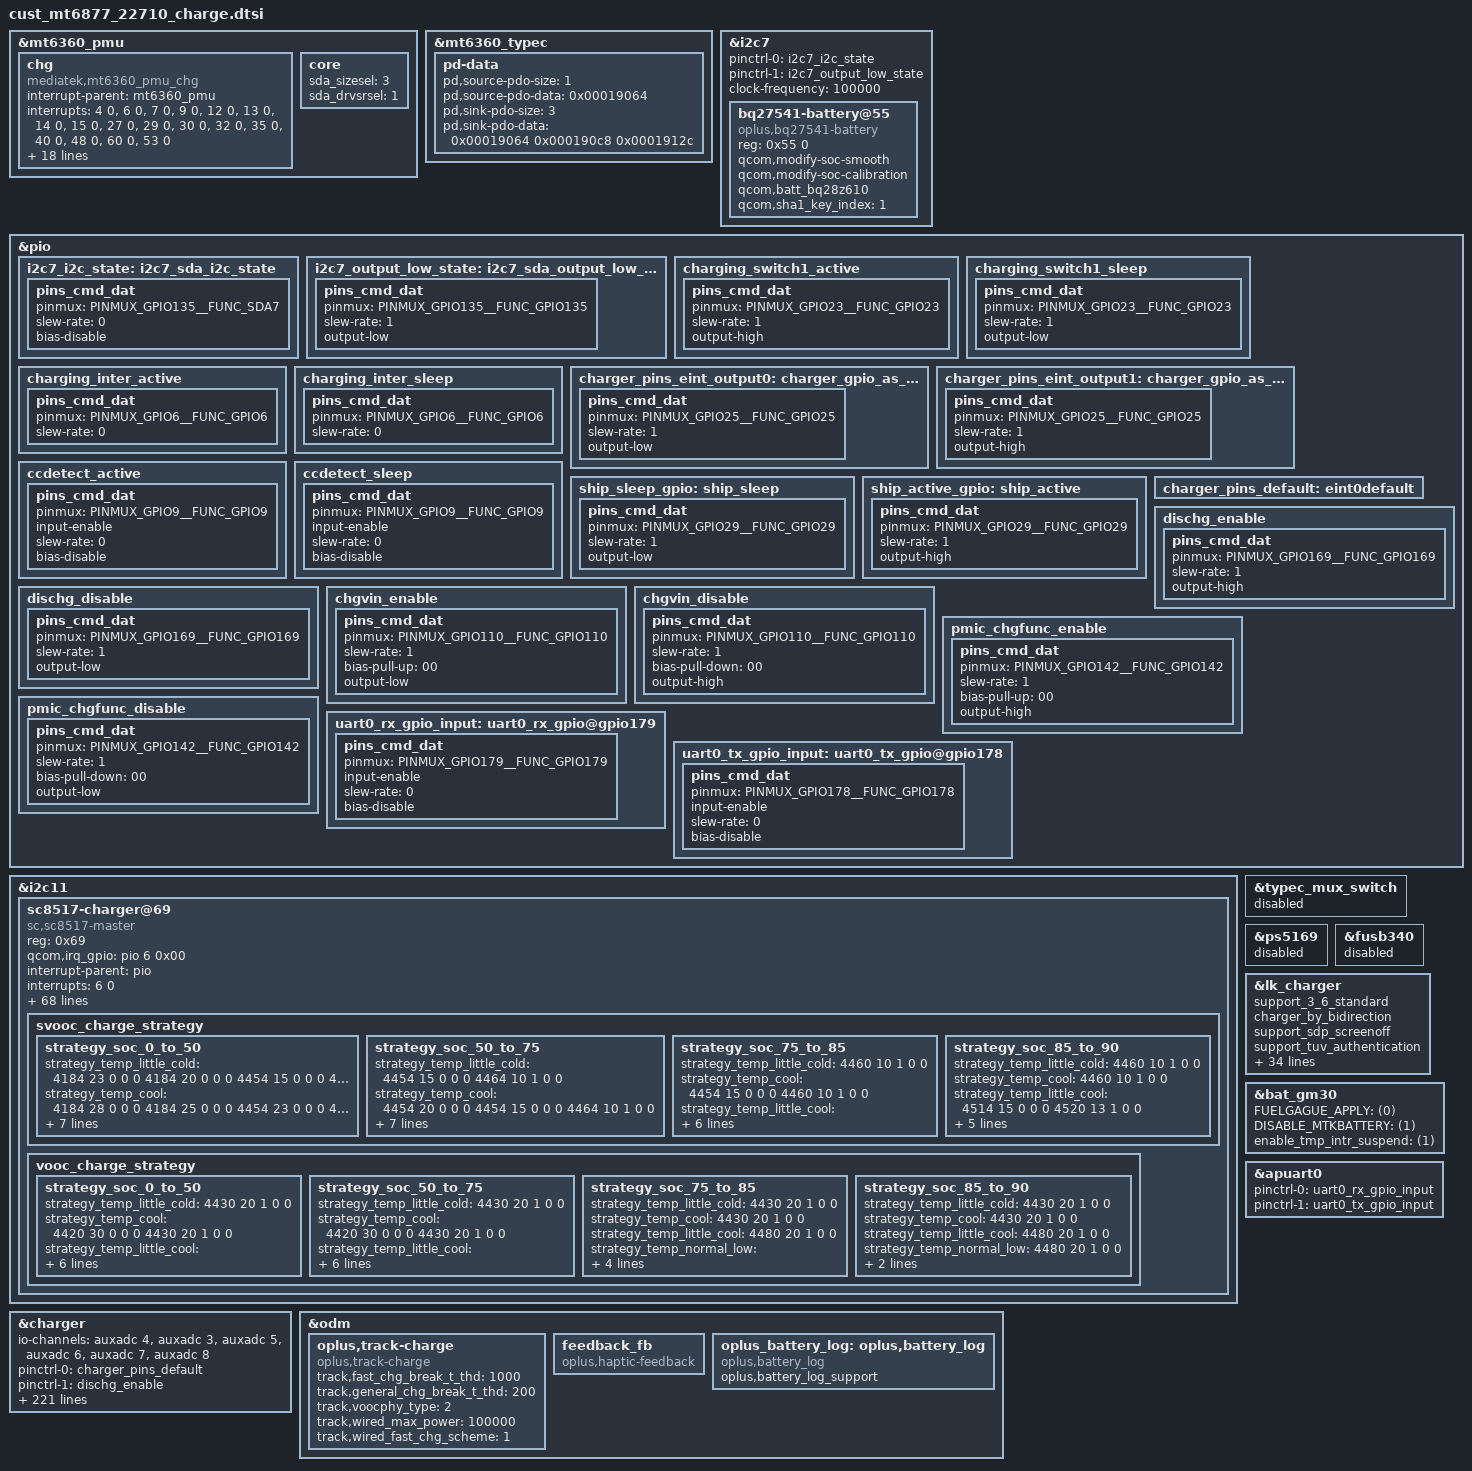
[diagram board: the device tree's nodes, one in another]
&mt6360_pmu {
	chg {
		compatible = "mediatek,mt6360_pmu_chg";
		interrupt-parent = <&mt6360_pmu>;
		interrupts = <4 0>, <6 0>, <7 0>, <9 0>,
				<12 0>, <13 0>, <14 0>, <15 0>,
				<27 0>, <29 0>, <30 0>, <32 0>,
				<35 0>, <40 0>, <48 0>, <60 0>,
				<53 0>;
		interrupt-names = "chg_treg_evt", "chg_mivr_evt",
				"pwr_rdy_evt", "chg_batsysuv_evt",
				"chg_vsysuv_evt", "chg_vsysov_evt",
				"chg_vbatov_evt", "chg_vbusov_evt",
				"chg_tmri", "chg_adpbadi",
				"chg_rvpi",  "chg_aiccmeasl",
				"wdtmri", "pumpx_donei",
				"attachi", "chrdet_ext_evt",
				"hvdcp_det";
		io-channels = <&adc 0>, <&adc 1>, <&adc 3>, <&adc 4>,
				<&adc 5>, <&adc 6>, <&adc 8>, <&adc 10>;
		io-channel-names = "USBID", "VBUSDIV5", "VSYS", "VBAT",
				"IBUS", "IBAT", "TEMP_JC", "TS";
		chg_name = "primary_chg";
		ichg = <2000000>;               /* uA */
		aicr = <500000>;                /* uA */
		mivr = <4400000>;               /* uV */
		cv = <4350000>;                 /* uA */
		ieoc = <150000>;                /* uA */
		safety_timer = <12>;            /* hour */
		ircmp_resistor = <25000>;       /* uohm */
		ircmp_vclamp = <32000>;         /* uV */
		en_te = <1>;
		en_wdt = <1>;
		aicc_once = <1>;
		post_aicc = <1>;
		batoc_notify = <0>;
	};
};

&mt6360_typec {
	pd-data {
		pd,source-pdo-size = <1>;
		pd,source-pdo-data = <0x00019064>; /* Fixed5V1A */

		pd,sink-pdo-size = <3>;
		pd,sink-pdo-data = <0x00019064 0x000190c8 0x0001912c>; /* Fixed5V1A Fixed5V2A Fixed5V3A */
	};
};

&mt6360_pmu {
	core {
		sda_sizesel = <3>;
		sda_drvsrsel = <1>;
	};
	chg {
		support_hvdcp;
		cdp_first_ignore;
	};
};

&i2c7 {
	pinctrl-names = "i2c-state", "output-low-state";
	pinctrl-0 = <&i2c7_i2c_state>;
	pinctrl-1 = <&i2c7_output_low_state>;
};
&pio {
	i2c7_i2c_state: i2c7_sda_i2c_state {
		pins_cmd_dat {
			pinmux = <PINMUX_GPIO135__FUNC_SDA7>;
			slew-rate = <0>;
			bias-disable;
		};
	};
	i2c7_output_low_state: i2c7_sda_output_low_state {
		pins_cmd_dat {
			pinmux = <PINMUX_GPIO135__FUNC_GPIO135>;
			slew-rate = <1>;
			output-low;
		};
	};
};

&i2c7 {
	status = "okay";
	clock-frequency = <100000>;

	bq27541-battery@55 {
		status = "okay";
		compatible = "oplus,bq27541-battery";
		reg = <0x55 0>;
		qcom,modify-soc-smooth;
		qcom,modify-soc-calibration;
		qcom,batt_bq28z610;
		qcom,sha1_key_index = <1>;
		//qcom,bq28z610_need_balancing;
	};
};

&i2c11 {
	sc8517-charger@69{
		status = "okay";
		compatible = "sc,sc8517-master";
		reg = <0x69>;

		qcom,irq_gpio = <&pio 6 0x00>;
		interrupt-parent = <&pio>;
		interrupts = <6 0>;

		pinctrl-names = "switch1_act_switch2_act", "switch1_sleep_switch2_sleep",
				"charging_inter_active", "charging_inter_sleep";
		pinctrl-0 = <&charging_switch1_active>;
		pinctrl-1 = <&charging_switch1_sleep>;
		pinctrl-2 = <&charging_inter_active>;
		pinctrl-3 = <&charging_inter_sleep>;

		qcom,charging_switch1-gpio = <&pio 23 0x00>;

		qcom,external_gauge_support;
		qcom,copycat_vooc_support;
		qcom,voocphy_bidirect_cp_support;
		qcom,voocphy_current_default = <100>;

		qcom,svooc_cool_down_current_limit = <100 10 15 20 25 30 35 40 45 50 55 60 63 65 70 75 80 85 100>;
		qcom,vooc_cool_down_current_limit = <60 20 20 20 30 40 50 60>;

		qcom,abnormal_adapter_current = <122 50 50 50 40 40 30 30 20 20>;
		qcom,vooc_little_cold_full_voltage = <4460>;
		qcom,vooc_cool_full_voltage = <4460>;
		qcom,vooc_warm_full_voltage = <4130>;
		qcom,vooc_1time_full_voltage = <4530>;
		qcom,vooc_ntime_full_voltage = <4520>;
		qcom,low_curr_full_t1 = <120>;
		qcom,low_curr_full_t2 = <350>;
		qcom,low_curr_full_t3 = <430>;
		qcom,range1_low_curr_full = <1000 4490
						950 4485
						800 4470
						700 4460
						500 4450>;
		qcom,range2_low_curr_full = <1150 4490
						1100 4485
						950 4470
						850 4460
						650 4450>;

		qcom,vooc_multistep_initial_batt_temp = <1000>;
		qcom,vooc_little_cool_temp = <200>;
		qcom,vooc_cool_temp = <120>;
		qcom,vooc_little_cold_temp = <50>;
		qcom,vooc_normal_low_temp = <350>;
		qcom,vooc_strategy_normal_current = <100>;
		qcom,vooc_normal_to_little_cool_current = <100>;
		qcom,vooc_batt_over_high_temp = <510>;
		qcom,vooc-low-temp = <0>;
		qcom,vooc-high-temp = <500>;
		qcom,vooc-low-soc = <0>;
		qcom,vooc-high-soc = <90>;
		qcom,vooc-normal-high-temp = <430>;
		qcom,vooc-warm-allow-vol = <4000>;
		qcom,vooc-warm-allow-soc = <50>;

		qcom,vooc_strategy1_batt_high_temp0 = <380>;
		qcom,vooc_strategy1_batt_high_temp1 = <400>;
		qcom,vooc_strategy1_batt_high_temp2 = <420>;
		qcom,vooc_strategy1_batt_low_temp2 = <410>;
		qcom,vooc_strategy1_batt_low_temp1 = <390>;
		qcom,vooc_strategy1_batt_low_temp0 = <370>;

		qcom,vooc_strategy1_high_current0 = <70>;
		qcom,vooc_strategy1_high_current1 = <60>;
		qcom,vooc_strategy1_high_current2 = <50>;
		qcom,vooc_strategy1_low_current2 = <60>;
		qcom,vooc_strategy1_low_current1 = <70>;
		qcom,vooc_strategy1_low_current0 = <80>;

		qcom,voocphy_ibat_over_current = <10600>;
		qcom,voocphy_cp_max_ibus = <6300>;
		qcom,voocphy_svooc_cp_max_ibus = <3500>;
		qcom,voocphy_vooc_cp_max_ibus = <3500>;
		qcom,batt_pwd_curr_thd1 = <3300>;
		qcom,batt_pwd_vol_thd1 = <4514>;

		qcom,voocphy_freq_mincore = <1800000>;
		qcom,voocphy_freq_midcore = <1800000>;
		qcom,voocphy_freq_maxcore = <1800000>;
		qcom,voocphy_current_change_timeout = <100>;

		svooc_batt_sys_curve = <1 0 1 0 0 0 0	// 8000mA
					1 0 1 1 1 0 0	// 4324mV
					0 0 1 0 1 0 0	// 2000mA
					1 1 1 0 0 1 0	// 4544mV
					0 0 0 1 1 0 0	// 1200mA
					1 1 1 0 0 1 0>; // 4544mV

		vooc_batt_sys_curve =  <0 1 0 1 1 0 1 	// 3000mA
					0 0 0 0 0 0 1	// 3414mV
					0 0 1 0 1 0 0	// 2000mA
					1 1 1 0 0 1 0	// 4544mV
					0 0 0 1 0 1 0	// 1000mA
					1 1 1 0 0 1 0>; // 4544mV

		svooc_charge_strategy {
			strategy_soc_0_to_50 {
				strategy_temp_little_cold =	<4184 23 0 0 0
								4184 20 0 0 0
								4454 15 0 0 0
								4460 10 1 0 0>;
				strategy_temp_cool =		<4184 28 0 0 0
								4184 25 0 0 0
								4454 23 0 0 0
								4454 20 0 0 0
								4454 15 0 0 0
								4460 10 1 0 0>;
				strategy_temp_little_cool = 	<4184 65 0 0 0
								4184 60 0 0 0
								4184 55 0 0 0
								4184 50 0 0 0
								4484 45 0 0 0
								4484 40 0 0 0
								4484 35 0 0 0
								4514 30 0 0 0
								4514 25 0 0 0
								4514 20 0 0 0
								4514 15 0 0 0
								4520 13 1 0 0>;
				strategy_temp_normal_low =	<4204 91 0 180 0
								4204 85 0 180 0
								4304 80 0 180 0
								4304 75 0 180 0
								4304 70 0 600 0
								4304 65 0 600 0
								4484 60 0 0 0
								4484 55 0 0 0
								4484 50 0 0 0
								4484 45 0 0 0
								4514 40 0 0 0
								4514 35 0 0 0
								4514 30 0 0 0
								4514 25 0 0 0
								4514 20 0 0 0
								4514 15 0 0 0
								4520 13 1 0 0>;
				strategy_temp_normal_high =	<4204 91 0 180 0
								4204 85 0 180 0
								4304 80 0 180 0
								4304 75 0 180 0
								4304 70 0 600 0
								4304 65 0 600 0
								4484 60 0 0 0
								4484 55 0 0 0
								4484 50 0 0 0
								4484 45 0 0 0
								4514 40 0 0 0
								4514 35 0 0 0
								4514 30 0 0 0
								4514 25 0 0 0
								4514 20 0 0 0
								4520 15 1 0 0>;
				strategy_temp_warm =		<4130 13 1 0 0>;
			};

			strategy_soc_50_to_75 {
				strategy_temp_little_cold =	<4454 15 0 0 0
								4464 10 1 0 0>;
				strategy_temp_cool =		<4454 20 0 0 0
								4454 15 0 0 0
								4464 10 1 0 0>;
				strategy_temp_little_cool =	<4484 45 0 0 0
								4484 40 0 0 0
								4484 35 0 0 0
								4514 30 0 0 0
								4514 25 0 0 0
								4514 20 0 0 0
								4514 15 0 0 0
								4520 13 1 0 0>;
				strategy_temp_normal_low =	<4484 50 0 0 0
								4484 45 0 0 0
								4514 40 0 0 0
								4514 35 0 0 0
								4514 30 0 0 0
								4514 25 0 0 0
								4514 20 0 0 0
								4514 15 0 0 0
								4520 13 1 0 0>;
				strategy_temp_normal_high =	<4484 50 0 0 0
								4484 45 0 0 0
								4514 40 0 0 0
								4514 35 0 0 0
								4514 30 0 0 0
								4514 25 0 0 0
								4514 20 0 0 0
								4520 15 1 0 0>;
				strategy_temp_warm =		<4130 12 1 0 0>;
			};

			strategy_soc_75_to_85 {
				strategy_temp_little_cold = 	<4460 10 1 0 0>;
				strategy_temp_cool =		<4454 15 0 0 0
								4460 10 1 0 0>;
				strategy_temp_little_cool =	<4514 30 0 0 0
								4514 25 0 0 0
								4514 20 0 0 0
								4514 15 0 0 0
								4520 13 1 0 0>;
				strategy_temp_normal_low =	<4514 35 0 0 0
								4514 30 0 0 0
								4514 25 0 0 0
								4514 20 0 0 0
								4514 15 0 0 0
								4520 13 1 0 0>;
				strategy_temp_normal_high =	<4514 35 0 0 0
								4514 30 0 0 0
								4514 25 0 0 0
								4514 20 0 0 0
								4520 15 1 0 0>;
				strategy_temp_warm =		<4130 12 1 0 0>;
			};

			strategy_soc_85_to_90 {
				strategy_temp_little_cold = 	<4460 10 1 0 0>;
				strategy_temp_cool =		<4460 10 1 0 0>;
				strategy_temp_little_cool =	<4514 15 0 0 0
					            4520 13 1 0 0>;
				strategy_temp_normal_low =	<4514 20 0 0 0
					            4514 15 0 0 0
								4520 13 1 0 0>;
				strategy_temp_normal_high =	<4514 20 0 0 0
								4520 15 1 0 0>;
				strategy_temp_warm =		<4130 12 1 0 0>;
			};
		};

		vooc_charge_strategy {
			strategy_soc_0_to_50 {
				strategy_temp_little_cold = 	<4430 20 1 0 0>;
				strategy_temp_cool =		<4420 30 0 0 0
								 4430 20 1 0 0>;
				strategy_temp_little_cool =	<4475 30 0 0 0
								 4480 20 1 0 0>;
				strategy_temp_normal_low =	<4475 30 0 0 0
								 4480 20 1 0 0>;
				strategy_temp_normal_high =	<4475 30 0 0 0
								 4480 20 1 0 0>;
				strategy_temp_warm =		<4130 24 1 0 0>;
			};

			strategy_soc_50_to_75 {
				strategy_temp_little_cold =	<4430 20 1 0 0>;
				strategy_temp_cool =		<4420 30 0 0 0
								 4430 20 1 0 0>;
				strategy_temp_little_cool =	<4475 30 0 0 0
								 4480 20 1 0 0>;
				strategy_temp_normal_low =	<4475 30 0 0 0
								 4480 20 1 0 0>;
				strategy_temp_normal_high =	<4475 30 0 0 0
								 4480 20 1 0 0>;
				strategy_temp_warm =		<4130 24 1 0 0>;
			};

			strategy_soc_75_to_85 {
				strategy_temp_little_cold =	<4430 20 1 0 0>;
				strategy_temp_cool =		<4430 20 1 0 0>;
				strategy_temp_little_cool =	<4480 20 1 0 0>;
				strategy_temp_normal_low =	<4475 30 0 0 0
								 4480 20 1 0 0>;
				strategy_temp_normal_high =	<4475 30 0 0 0
								 4480 20 1 0 0>;
				strategy_temp_warm =		<4130 24 1 0 0>;
			};

			strategy_soc_85_to_90 {
				strategy_temp_little_cold =	<4430 20 1 0 0>;
				strategy_temp_cool =		<4430 20 1 0 0>;
				strategy_temp_little_cool =	<4480 20 1 0 0>;
				strategy_temp_normal_low =	<4480 20 1 0 0>;
				strategy_temp_normal_high =	<4480 20 1 0 0>;
				strategy_temp_warm =		<4130 24 1 0 0>;
			};
		};
	};
};

&typec_mux_switch {
	status = "disabled";
};

&ps5169{
	status = "disabled";
};

&fusb340 {
	status = "disabled";
};

&pio {
	charging_switch1_active: charging_switch1_active {
		pins_cmd_dat {
			pinmux = <PINMUX_GPIO23__FUNC_GPIO23>;
			slew-rate = <1>;
			output-high;
		};
	};
	charging_switch1_sleep: charging_switch1_sleep {
		pins_cmd_dat {
			pinmux = <PINMUX_GPIO23__FUNC_GPIO23>;
			slew-rate = <1>;
			output-low;
		};
	};

	charging_inter_active: charging_inter_active {
		pins_cmd_dat {
			pinmux = <PINMUX_GPIO6__FUNC_GPIO6>;
			slew-rate = <0>;
        };
    };
	charging_inter_sleep: charging_inter_sleep {
		pins_cmd_dat {
            pinmux = <PINMUX_GPIO6__FUNC_GPIO6>;
            slew-rate = <0>;
        };
    };

	charger_pins_eint_output0: charger_gpio_as_output_low {
		pins_cmd_dat {
			pinmux = <PINMUX_GPIO25__FUNC_GPIO25>;
			slew-rate = <1>;
			output-low;
		};
	};

	charger_pins_eint_output1: charger_gpio_as_output_high {
		pins_cmd_dat {
			pinmux = <PINMUX_GPIO25__FUNC_GPIO25>;
			slew-rate = <1>;
			output-high;
		};
	};
	ccdetect_active: ccdetect_active {
		pins_cmd_dat {
			pinmux = <PINMUX_GPIO9__FUNC_GPIO9>;
			input-enable;
			slew-rate = <0>;
			bias-disable;
		};
	};
	ccdetect_sleep: ccdetect_sleep {
		pins_cmd_dat {
			pinmux = <PINMUX_GPIO9__FUNC_GPIO9>;
			input-enable;
			slew-rate = <0>;
			bias-disable;
		};
	};

	ship_sleep_gpio: ship_sleep {
		pins_cmd_dat {
			pinmux = <PINMUX_GPIO29__FUNC_GPIO29>;
			slew-rate = <1>;
			output-low;
		};
	};

	ship_active_gpio: ship_active {
		pins_cmd_dat {
			pinmux = <PINMUX_GPIO29__FUNC_GPIO29>;
			slew-rate = <1>;
			output-high;
		};
	};
};

&charger {
	io-channels =  <&auxadc 4>,<&auxadc 3>, <&auxadc 5>,
		<&auxadc 6>, <&auxadc 7>, <&auxadc 8>;
	io-channel-names = "auxadc6-subboard_temp","auxadc3-chargeric_temp","auxadc4-usb_temp_v_l",
		"auxadc5-usb_temp_v_r","usbcon_temp","batcon_temp";

	pinctrl-names = "default",
				"dischg_enable",
				"dischg_disable",
				"charger_gpio_as_output_low",
				"charger_gpio_as_output_high",
				"ccdetect_active",
				"ccdetect_sleep",
				"chgvin_enable",
				"chgvin_disable",
				"pmic_chgfunc_enable",
				"pmic_chgfunc_disable",
				"ship_active",
				"ship_sleep";
	pinctrl-0 = <&charger_pins_default>;
	pinctrl-1 = <&dischg_enable>;
	pinctrl-2 = <&dischg_disable>;
	pinctrl-3 = <&charger_pins_eint_output0>;
	pinctrl-4 = <&charger_pins_eint_output1>;
	pinctrl-5 = <&ccdetect_active>;
	pinctrl-6 = <&ccdetect_sleep>;
	pinctrl-7 = <&chgvin_enable>;
	pinctrl-8 = <&chgvin_disable>;
	pinctrl-9 = <&pmic_chgfunc_enable>;
	pinctrl-10 = <&pmic_chgfunc_disable>;
	pinctrl-11 = <&ship_active_gpio>;
	pinctrl-12 = <&ship_sleep_gpio>;

	qcom,pd_input_current_charger_ma = <1500>;
	qcom,qc_input_current_charger_ma = <1500>;
	qcom,input_current_charger_ma = <2000>;
	qcom,input_current_usb_ma = <500>;
	qcom,input_current_cdp_ma = <1500>;
	qcom,input_current_camera_ma = <1200>;
	qcom,input_current_calling_ma = <1500>;

	qcom,led_warm_bat_decidegc = <350>;
	qcom,led_high_bat_decidegc = <370>;
	qcom,input_current_led_ma = <1200>;
	qcom,input_current_led_ma_high = <1200>;
	qcom,input_current_led_ma_warm = <1500>;
	qcom,input_current_led_ma_normal = <2300>;
	qcom,input_current_led_ma_forcmcc = <500>;
	qcom,input_current_led_ma_limit_high = <1200>;

	qcom,vooc_temp_bat_normal_decidegc = <350>;
	qcom,vooc_temp_bat_warm_decidegc = <370>;
	qcom,vooc_temp_bat_hot_decidegc = <510>;
	qcom,input_current_vooc_led_ma_high = <1200>;
	qcom,input_current_vooc_led_ma_warm = <1800>;
	qcom,input_current_vooc_led_ma_normal = <3600>;
	qcom,input_current_vooc_ma_normal = <3600>;
	qcom,input_current_vooc_ma_warm = <3200>;
	qcom,input_current_vooc_ma_high = <2200>;

	qcom,overtemp_bat_decidegc = <350>;
	qcom,iterm_disabled = <0>;
	//sw_full_count = <25>;
	qcom,iterm_ma = <132>;
	qcom,recharge-mv = <100>;

	qcom,batt_capacity_mah = <5000>; /*typical capacity*/
	//qcom,batt_capacity_mah = <4880>; /*rated capacity*/
	qcom,usb_high_than_bat_decidegc = <168>;

	qcom,removed_bat_decidegc = <390>;  /* < -15C */

	qcom,cold_bat_decidegc = <100>;  /* -2C ~ 0C */
	qcom,temp_cold_vfloat_mv = <4465>;
	qcom,temp_cold_fastchg_current_ma = <1000>;

	qcom,little_cold_bat_decidegc = <0>;    /* 0C ~ 5C */
	qcom,temp_little_cold_vfloat_mv = <4465>;
	qcom,temp_little_cold_fastchg_current_ma_high = <2200>;
	qcom,temp_little_cold_fastchg_current_ma_low = <2200>;
	qcom,temp_little_cold_fastchg_current_ma = <1076>;
	qcom,qc_temp_little_cold_fastchg_current_ma_high = <2594>;
	qcom,qc_temp_little_cold_fastchg_current_ma_low = <3300>;
	qcom,pd_temp_little_cold_fastchg_current_ma_high = <2594>;
	qcom,pd_temp_little_cold_fastchg_current_ma_low = <3300>;

	qcom,cool_bat_decidegc = <50>;  /* 5C ~ 12C */
	qcom,temp_cool_vfloat_mv = <4465>;
	qcom,temp_cool_fastchg_current_ma_high = <2200>;
	qcom,temp_cool_fastchg_current_ma_low = <2200>;
	qcom,qc_temp_cool_fastchg_current_ma_high = <3300>;
	qcom,qc_temp_cool_fastchg_current_ma_low = <3300>;
	qcom,pd_temp_cool_fastchg_current_ma_high = <3300>;
	qcom,pd_temp_cool_fastchg_current_ma_low = <3300>;

	qcom,little_cool_bat_decidegc = <120>;  /* 12C ~ 16C */
	qcom,temp_little_cool_vfloat_mv = <4465>;
	qcom,temp_little_cool_fastchg_current_ma = <2200>;
	qcom,pd_temp_little_cool_fastchg_current_ma = <3300>;
	qcom,qc_temp_little_cool_fastchg_current_ma = <3300>;

	qcom,normal_bat_decidegc = <160>;       /* 16C ~ 45C */
	qcom,temp_normal_vfloat_mv = <4465>;
	qcom,temp_normal_fastchg_current_ma = <2200>;
	qcom,pd_temp_normal_fastchg_current_ma = <3300>;
	qcom,qc_temp_normal_fastchg_current_ma = <3300>;

	qcom,warm_bat_decidegc = <450>;         /* 45C ~ 53C */ /*8pin Bat Vooc project need add 3 degree C*/
	qcom,temp_warm_vfloat_mv = <4130>;
	qcom,temp_warm_fastchg_current_ma = <2200>;
	qcom,pd_temp_warm_fastchg_current_ma = <2200>;
	qcom,qc_temp_warm_fastchg_current_ma = <2200>;
	qcom,temp_warm_fastchg_current_ma_led_on = <1000>;

	qcom,hot_bat_decidegc = <530>;  /* > 53C */

	qcom,non_standard_vfloat_mv = <3980>;
	qcom,non_standard_fastchg_current_ma = <512>;
	qcom,support_subboard_ntc;

	qcom,short_c_bat_cv_mv = <4330>;
	qcom,short_c_bat_vfloat_mv = <3800>;
	qcom,short_c_bat_fastchg_current_ma = <512>;
	qcom,short_c_bat_vfloat_sw_limit = <3750>;

	qcom,cold_vfloat_sw_limit = <4415>;
	qcom,little_cold_vfloat_sw_limit = <4415>;
	qcom,cool_vfloat_sw_limit = <4415>;
	qcom,little_cool_vfloat_sw_limit = <4415>;
	qcom,normal_vfloat_sw_limit = <4415>;
	qcom,warm_vfloat_sw_limit = <4080>;
	qcom,non_standard_vfloat_sw_limit = <3930>;

	qcom,max_chg_time_sec = <72000>;
	qcom,charger_hv_thr = <10000>;
	qcom,charger_recv_thr = <9800>;
	qcom,charger_lv_thr = <3400>;
	qcom,vbatt_full_thr = <4400>;
	qcom,vbatt_hv_thr = <4600>;

	qcom,vfloat_step_mv = <16>;
	qcom,non_standard_vfloat_over_sw_limit = <3990>;
	qcom,cold_vfloat_over_sw_limit = <4475>;
	qcom,little_cold_vfloat_over_sw_limit = <4475>;
	qcom,cool_vfloat_over_sw_limit = <4475>;
	qcom,little_cool_vfloat_over_sw_limit = <4475>;
	qcom,normal_vfloat_over_sw_limit = <4475>;
	qcom,warm_vfloat_over_sw_limit = <4140>;

	qcom,usbtemp_batt_temp_low = <50>;
	qcom,usbtemp_batt_temp_high = <50>;
	qcom,usbtemp_ntc_temp_low = <57>;
	qcom,usbtemp_ntc_temp_high = <69>;
	qcom,usbtemp_temp_gap_low_with_batt_temp = <7>;
	qcom,usbtemp_temp_gap_high_with_batt_temp = <12>;
	qcom,usbtemp_temp_gap_low_without_batt_temp = <12>;
	qcom,usbtemp_temp_gap_high_without_batt_temp = <24>;
	qcom.usbtemp_rise_fast_temp_low = <3>;
	qcom.usbtemp_rise_fast_temp_high = <3>;
	qcom.usbtemp_rise_fast_temp_count_low = <30>;
	qcom.usbtemp_rise_fast_temp_count_high = <20>;

	qcom,usbtemp_cool_down_ntc_low = <54>;
	qcom,usbtemp_cool_down_ntc_high = <65>;
	qcom,usbtemp_cool_down_gap_low = <12>;
	qcom,usbtemp_cool_down_gap_high = <20>;
	qcom,usbtemp_cool_down_recover_ntc_low = <48>;
	qcom,usbtemp_cool_down_recover_ntc_high = <60>;
	qcom,usbtemp_cool_down_recover_gap_low = <6>;
	qcom,usbtemp_cool_down_recover_gap_high = <15>;

	qcom,hv_flashled_support;
	qcom,vbatt_power_off = <3300>;
	qcom,vbatt_soc_1 = <3410>;
	qcom,vooc_project = <8>;
	qcom,vbatt_num = <2>;
	qcom,new_ui_warning_support;
	qcom,smart_charging_screenoff;
	qcom,smart_charge_version = <1>;

	qcom,normal_vterm_hw_inc = <18>;
	qcom,non_normal_vterm_hw_inc = <18>;
	qcom,usbtemp_batttemp_gap = <12>;
	full_pre_ffc_judge;
	full-pre-ffc-mv = <4455>;

	qcom,ff1_normal_fastchg_ma = <1100>;
	qcom,ff1_warm_fastchg_ma = <1100>;	/* 35C ~ 40c */
	qcom,ff1_exit_step_ma = <700>;
	qcom,ff1_warm_exit_step_ma = <700>;
	qcom,ffc2_normal_fastchg_ma = <700>;/*12C~35c*/
	qcom,ffc2_warm_fastchg_ma = <700>;	/* 35C ~ 40c */
	qcom,ffc2_temp_warm_decidegc = <350>;
	qcom,ffc2_temp_high_decidegc = <400>;
	qcom,ffc2_temp_low_decidegc = <120>;
	qcom,ffc2_exit_step_ma = <500>;
	qcom,ffc2_warm_exit_step_ma = <200>;

	qcom,ffc_normal_vfloat_sw_limit = <4480>;
	qcom,ffc2_normal_vfloat_sw_limit = <4465>;
	qcom,ffc2_warm_vfloat_sw_limit = <4465>;
	qcom,ffc_temp_normal_vfloat_mv = <4540>;
	qcom,ffc1_temp_normal_vfloat_mv = <4540>;
	qcom,ffc2_temp_normal_vfloat_mv = <4540>;
	qcom,ffc_normal_vfloat_over_sw_limit = <4540>;
	qcom,ffc1_normal_vfloat_over_sw_limit = <4540>;
	qcom,ffc2_normal_vfloat_over_sw_limit = <4540>;

	qcom,default_iterm_ma = <132>;
	qcom,default_temp_normal_fastchg_current_ma = <2200>;
	qcom,default_normal_vfloat_sw_limit = <4415>;
	qcom,default_temp_normal_vfloat_mv = <4465>;
	qcom,default_normal_vfloat_over_sw_limit = <4475>;
	qcom,default_temp_little_cool_fastchg_current_ma = <2200>;
	qcom,default_little_cool_vfloat_sw_limit = <4415>;
	qcom,default_temp_little_cool_vfloat_mv = <4465>;
	qcom,default_little_cool_vfloat_over_sw_limit = <4475>;
	//qcom,usbtemp_dischg_by_pmic;
	qcom,support_usbtemp_protect_v2;
	oplus,pdqc_9v_voltage_adaptive;
	//for PD9V or QC9V
	qcom,vbatt_pdqc_to_5v_thr = <4500>;
	qcom,vbatt_pdqc_to_9v_thr = <4500>;
	qcom,vooc-max-input-volt-support = <11000>;     //11V
	qcom,vooc-max-input-current-support = <9100>;   //9.1A
	//for control:
	//qcom,suspend_after_full;
	qcom,check_batt_full_by_sw;
	qcom,chg_ctrl_by_lcd;
	qcom,chg_ctrl_by_camera;
	qcom,chg_ctrl_by_calling;
	qcom,sw_vfloat_over_protect_enable;
	qcom,ffc_support;
	qcom,dual_ffc;
	qcom,chargerid_vol_disable;
	qcom,support_ntc_01c_precision;
	qcom,voocphy_support = <(2)>; // AP_SINGLE_CP_VOOCPHY
	voocphy_support_display_vooc;
	//qcom,external_authenticate;
	qcom,external_gauge;
	qcom,chargerid_support;
	qcom,vooc_show_ui_soc_decimal;
	qcom,ui_soc_decimal_speedmin = <20>;//2A
	oplus,smooth_switch_v2;
	oplus,reserve_chg_soc = <3>;
	oplus,reserve_dis_soc = <3>;

	qcom,chg_ctrl_by_vooc;
	qcom,support_abnormal_adapter;
	qcom,charger_current_vooc_ma_normal = <3000>;

	qcom,smart_chg_bcc_support;
	oplus,quick_mode_gain_support;
	qcom,smart_chg_soh_support;
	oplus,aging_ffc_version = <1>;

	//GPIO config
	qcom,chargerid_switch-gpio = <&pio 25 0x00>;
	qcom,dischg-gpio = <&pio 169 0x00>;
	qcom,ccdetect-gpio = <&pio 9 0x00>;
	qcom,chgvin = <&pio 110 0x00>;
	qcom,pmic_chgfunc = <&pio 142 0x00>;
	qcom,ship-gpio = <&pio 29 0x00>;
};

&lk_charger{
	support_3_6_standard;
	charger_by_bidirection;
	support_sdp_screenoff;
	support_tuv_authentication;
	sub_board_temp_support;
	sub_board_temp_adc_channel = <5>;
	max_charger_voltage = <9900000>;
	support_new_charger_stander;
	usb_charger_current = <500000>;
	ac_charger_input_current = <2000000>;
	non_std_ac_charger_current = <2000000>;
	charging_host_charger_current = <1500000>;
	precharge_1_step_current = <350>;

	cold_bat_decidegc = <10>;  /*-10C~0C*/
	dcp_temp_cold_fastchg_current = <600>;
	usb_temp_cold_fastchg_current = <600>;
	cdp_temp_cold_fastchg_current = <600>;

	little_cold_bat_decidegc = <0>;    /*0C~5C*/
	dcp_temp_little_cold_fastchg_current = <1000>;
	usb_temp_little_cold_fastchg_current = <600>;
	cdp_temp_little_cold_fastchg_current = <1000>;

	cool_bat_decidegc = <5>;  /*5C~12C*/
	dcp_temp_cool_fastchg_current = <1600>;
	usb_temp_cool_fastchg_current = <600>;
	cdp_temp_cool_fastchg_current = <1600>;

	little_cool_bat_decidegc = <12>;  /*12C~16C*/
	dcp_temp_little_cool_fastchg_current = <2200>;
	usb_temp_little_cool_fastchg_current = <600>;
	cdp_temp_little_cool_fastchg_current = <1600>;

	normal_bat_decidegc = <16>;       /*16C~45C*/
	dcp_temp_normal_fastchg_current = <2200>;
	usb_temp_normal_fastchg_current = <600>;
	cdp_temp_normal_fastchg_current = <1600>;

	warm_bat_decidegc = <45>;    /*45C~53C*/
	dcp_temp_warm_fastchg_current = <2200>;
	usb_temp_warm_fastchg_current = <600>;
	cdp_temp_warm_fastchg_current = <1600>;

	hot_bat_decidegc = <53>;
};

&bat_gm30 {
	FUELGAGUE_APPLY = <(0)>;
	DISABLE_MTKBATTERY = <(1)>;
	enable_tmp_intr_suspend = <(1)>;
};

&pio {
	charger_pins_default: eint0default {
	};

	dischg_enable: dischg_enable {
		pins_cmd_dat {
			pinmux = <PINMUX_GPIO169__FUNC_GPIO169>;
			slew-rate = <1>;//0:input direction 1:output direction
			output-high;
		};
	};

	dischg_disable: dischg_disable {
		pins_cmd_dat {
			pinmux = <PINMUX_GPIO169__FUNC_GPIO169>;
			slew-rate = <1>;
			output-low;
		};
	};

	chgvin_enable: chgvin_enable {
        pins_cmd_dat {
			pinmux = <PINMUX_GPIO110__FUNC_GPIO110>;
			slew-rate = <1>;//0:input direction 1:output direction
			bias-pull-up = <00>;
			output-low;
		};
    };

	chgvin_disable: chgvin_disable {
		pins_cmd_dat {
			pinmux = <PINMUX_GPIO110__FUNC_GPIO110>;
			slew-rate = <1>;
			bias-pull-down = <00>;
			output-high;
		};
	};

	pmic_chgfunc_enable: pmic_chgfunc_enable {
		pins_cmd_dat {
			pinmux = <PINMUX_GPIO142__FUNC_GPIO142>;
			slew-rate = <1>;//0:input direction 1:output direction
			bias-pull-up = <00>;
			output-high;
		};
	};

	pmic_chgfunc_disable: pmic_chgfunc_disable {
		pins_cmd_dat {
			pinmux = <PINMUX_GPIO142__FUNC_GPIO142>;    /*6360 主充CHG_ENB*/
			slew-rate = <1>;
			bias-pull-down = <00>;
			output-low;
		};
	};
};


&apuart0 {
	pinctrl-names = "uart0_rx_gpio",
			"uart0_tx_gpio";
	pinctrl-0 = <&uart0_rx_gpio_input>;
	pinctrl-1 = <&uart0_tx_gpio_input>;
	status = "okay";
};

&pio {
	uart0_rx_gpio_input:uart0_rx_gpio@gpio179 {
		pins_cmd_dat {
			pinmux = <PINMUX_GPIO179__FUNC_GPIO179>;
			input-enable;
			slew-rate = <0>;
			bias-disable;
		};
	};
	uart0_tx_gpio_input:uart0_tx_gpio@gpio178 {
		pins_cmd_dat {
			pinmux = <PINMUX_GPIO178__FUNC_GPIO178>;
			input-enable;
			slew-rate = <0>;
			bias-disable;
		};
	};
};

&odm {
	oplus,track-charge {
		compatible = "oplus,track-charge";
		track,fast_chg_break_t_thd = <1000>;
		track,general_chg_break_t_thd = <200>;
		track,voocphy_type = <2>;
		track,wired_max_power = <100000>;
		track,wired_fast_chg_scheme = <1>;
	};
	feedback_fb: feedback_fb {
		compatible = "oplus,haptic-feedback";
	};
	oplus_battery_log: oplus,battery_log {
		compatible = "oplus,battery_log";
		oplus,battery_log_support;
	};
};
